[part 1 of 3: packages /HuaweiMDC to /HuaweiMDC/exe_manifests/exes]
AUTOSAR XML (schema 00048)
package /HuaweiMDC
  std cpp implementation data type CameraStructContainer: category=STRUCTURE
    namespaces:
      symbol props iflyauto
      symbol props camera_struct_container
    cpp implementation data type element meta_data: type-reference=String
    cpp implementation data type element camera_data: type-reference=rawBuffer
package /HuaweiMDC/process_manifests/processes
  18 x process, all with log-trace-default-log-level=INFO, log-trace-log-modes=NETWORK:
    com_service_pnc_node_libProcess1: design=com_service_pnc_node_libProcessDesign2, executable=com_service_pnc_node_exec
    control_libProcess2: design=control_libProcessDesign3, executable=control_exec
    obstacle_fusion_libProcess3: design=obstacle_fusion_libProcessDesign4, executable=obstacle_fusion_exec
    static_fusion_libProcess4: design=static_fusion_libProcessDesign5, executable=static_fusion_exec
    finite_state_manager_libProcess5: design=finite_state_manager_libProcessDesign6, executable=finite_state_manager_exec
    localization_libProcess7: design=localization_libProcessDesign8, executable=localization_exec
    ehr_libProcess8: design=ehr_libProcessDesign9, executable=ehr_exec
    panorama_view_camera_perception_libProcess10: design=panorama_view_camera_perception_libProcessDesign11, executable=panorama_view_camera_perception_exec
    uss_perception_libProcess12: design=uss_perception_libProcessDesign13, executable=uss_perception_exec
    planning_libProcess13: design=planning_libProcessDesign14, executable=planning_exec
    camera_node_around_view_libProcess15: design=camera_node_around_view_libProcessDesign16, executable=camera_node_around_view_exec
    camera_node_panorama_view_libProcess16: design=camera_node_panorama_view_libProcessDesign17, executable=camera_node_panorama_view_exec
    gnss_service_node_libProcess17: design=gnss_service_node_libProcessDesign18, executable=gnss_service_node_exec
    soc_a_communication_libProcess18: design=soc_a_communication_libProcessDesign19, executable=soc_a_communication_exec
    soc_b_communication_libProcess19: design=soc_b_communication_libProcessDesign20, executable=soc_b_communication_exec
    common_swc_libProcess22: design=common_swc_libProcessDesign23, executable=common_swc_exec1
    common_swc_libProcess23: design=common_swc_libProcessDesign24, executable=common_swc_exec2
    calibration_libProcess20: design=calibration_libProcessDesign21, executable=calibration_exec
package /HuaweiMDC/process_manifests/processDesigns
  19 x process design:
    com_service_pnc_node_libProcessDesign2: executable=com_service_pnc_node_exec
    control_libProcessDesign3: executable=control_exec
    obstacle_fusion_libProcessDesign4: executable=obstacle_fusion_exec
    static_fusion_libProcessDesign5: executable=static_fusion_exec
    finite_state_manager_libProcessDesign6: executable=finite_state_manager_exec
    localization_libProcessDesign8: executable=localization_exec
    ehr_libProcessDesign9: executable=ehr_exec
    panorama_view_camera_perception_libProcessDesign11: executable=panorama_view_camera_perception_exec
    uss_perception_libProcessDesign13: executable=uss_perception_exec
    planning_libProcessDesign14: executable=planning_exec
    camera_node_around_view_libProcessDesign16: executable=camera_node_around_view_exec
    camera_node_panorama_view_libProcessDesign17: executable=camera_node_panorama_view_exec
    gnss_service_node_libProcessDesign18: executable=gnss_service_node_exec
    soc_a_communication_libProcessDesign19: executable=soc_a_communication_exec
    soc_b_communication_libProcessDesign20: executable=soc_b_communication_exec
    diagnosis_b_libProcessDesign22
    common_swc_libProcessDesign23: executable=common_swc_exec1
    common_swc_libProcessDesign24: executable=common_swc_exec2
    calibration_libProcessDesign21: executable=calibration_exec
package /HuaweiMDC/process_manifests/processToMachineMappingSets
  17 x process to machine mapping set:
    ProcessToMachineMappingSet_panorama_view_camera_perception_libProcess10
      process to machine mapping processToMachineMapping1: machine=MdcSocBMachine, process=panorama_view_camera_perception_libProcess10
    ProcessToMachineMappingSet_camera_node_panorama_view_libProcess16
      process to machine mapping processToMachineMapping3: machine=MdcSocBMachine, process=camera_node_panorama_view_libProcess16
    ProcessToMachineMappingSet_camera_node_around_view_libProcess15
      process to machine mapping processToMachineMapping5: machine=MdcSocAMachine, process=camera_node_around_view_libProcess15
    ProcessToMachineMappingSet_soc_a_communication_libProcess18
      process to machine mapping processToMachineMapping6: machine=MdcSocAMachine, process=soc_a_communication_libProcess18
    ProcessToMachineMappingSet_ehr_libProcess8
      process to machine mapping processToMachineMapping11: machine=MdcSocBMachine, process=ehr_libProcess8
    ProcessToMachineMappingSet_diagnosis_b_libProcess21
      process to machine mapping processToMachineMapping12: machine=MdcSocBMachine
    ProcessToMachineMappingSet_soc_b_communication_libProcess19
      process to machine mapping processToMachineMapping18: machine=MdcSocBMachine, process=soc_b_communication_libProcess19
    ProcessToMachineMappingSet_gnss_service_node_libProcess17
      process to machine mapping processToMachineMapping19: machine=MdcSocBMachine, process=gnss_service_node_libProcess17
    ProcessToMachineMappingSet_localization_libProcess7
      process to machine mapping processToMachineMapping21: machine=MdcSocBMachine, process=localization_libProcess7
    ProcessToMachineMappingSet_uss_perception_libProcess12
      process to machine mapping processToMachineMapping22: machine=MdcSocBMachine, process=uss_perception_libProcess12
    ProcessToMachineMappingSet_static_fusion_libProcess4
      process to machine mapping processToMachineMapping30: machine=MdcSocAMachine, process=static_fusion_libProcess4
    ProcessToMachineMappingSet_control_libProcess2
      process to machine mapping processToMachineMapping32: machine=MdcSocAMachine, process=control_libProcess2
    ProcessToMachineMappingSet_planning_libProcess13
      process to machine mapping processToMachineMapping32: machine=MdcSocAMachine, process=planning_libProcess13
    ProcessToMachineMappingSet_obstacle_fusion_libProcess3
      process to machine mapping processToMachineMapping32: machine=MdcSocAMachine, process=obstacle_fusion_libProcess3
    ProcessToMachineMappingSet_com_service_pnc_node_libProcess1
      process to machine mapping processToMachineMapping32: machine=MdcSocAMachine, process=com_service_pnc_node_libProcess1
    ProcessToMachineMappingSet_calibration_libProcess20
      process to machine mapping processToMachineMapping32: machine=MdcSocBMachine, process=calibration_libProcess20
    ProcessToMachineMappingSet_finite_state_manager_libProcess5
      process to machine mapping processToMachineMapping31: machine=MdcSocBMachine, process=finite_state_manager_libProcess5
package /HuaweiMDC/exe_manifests/swcs
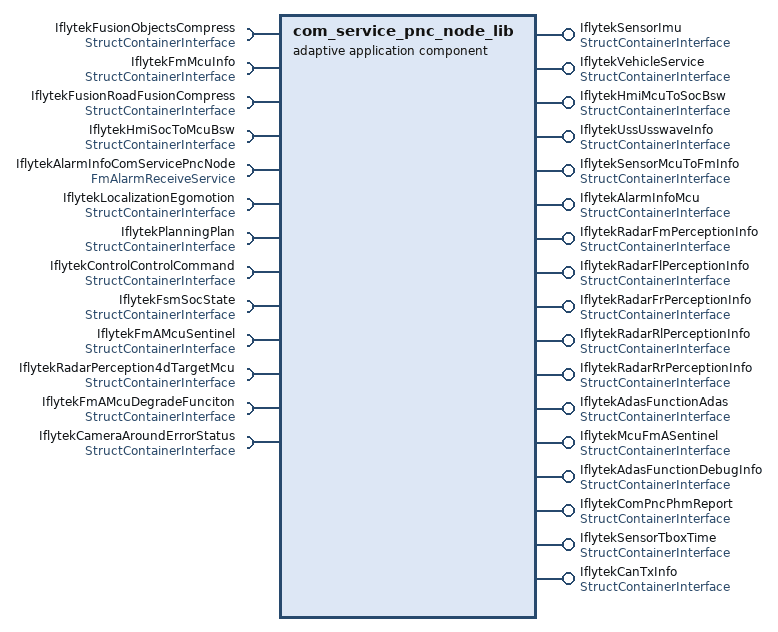
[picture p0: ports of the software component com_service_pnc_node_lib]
  adaptive application sw component type com_service_pnc_node_lib
    12 x provide port, all with provided-interface=StructContainerInterface:
      IflytekSensorImu
      IflytekVehicleService
      IflytekHmiMcuToSocBsw
      IflytekUssUsswaveInfo
      IflytekSensorMcuToFmInfo
      IflytekAlarmInfoMcu
      IflytekRadarFmPerceptionInfo
      IflytekRadarFlPerceptionInfo
      IflytekRadarFrPerceptionInfo
      IflytekRadarRlPerceptionInfo
      IflytekRadarRrPerceptionInfo
      IflytekAdasFunctionAdas
    9 x require port:
      IflytekFusionObjectsCompress: required-interface=StructContainerInterface
      IflytekFmMcuInfo: required-interface=StructContainerInterface
      IflytekFusionRoadFusionCompress: required-interface=StructContainerInterface
      IflytekHmiSocToMcuBsw: required-interface=StructContainerInterface
      IflytekAlarmInfoComServicePncNode: required-interface=FmAlarmReceiveService
      IflytekLocalizationEgomotion: required-interface=StructContainerInterface
      IflytekPlanningPlan: required-interface=StructContainerInterface
      IflytekControlControlCommand: required-interface=StructContainerInterface
      IflytekFsmSocState: required-interface=StructContainerInterface
    provide port IflytekMcuFmASentinel: provided-interface=StructContainerInterface
    require port IflytekFmAMcuSentinel: required-interface=StructContainerInterface
    provide port IflytekAdasFunctionDebugInfo: provided-interface=StructContainerInterface
    require port IflytekRadarPerception4dTargetMcu: required-interface=StructContainerInterface
    require port IflytekFmAMcuDegradeFunciton: required-interface=StructContainerInterface
    provide port IflytekComPncPhmReport: provided-interface=StructContainerInterface
    provide port IflytekSensorTboxTime: provided-interface=StructContainerInterface
    require port IflytekCameraAroundErrorStatus: required-interface=StructContainerInterface
    provide port IflytekCanTxInfo: provided-interface=StructContainerInterface
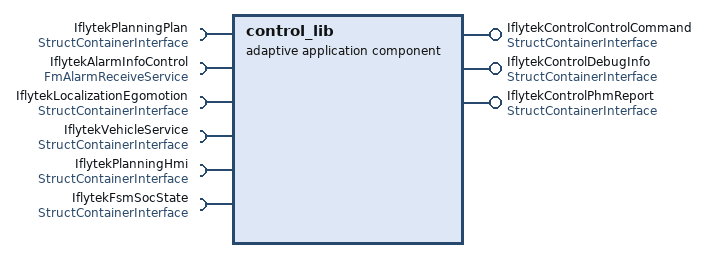
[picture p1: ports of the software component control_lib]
  adaptive application sw component type control_lib
    provide port IflytekControlControlCommand: provided-interface=StructContainerInterface
    6 x require port:
      IflytekPlanningPlan: required-interface=StructContainerInterface
      IflytekAlarmInfoControl: required-interface=FmAlarmReceiveService
      IflytekLocalizationEgomotion: required-interface=StructContainerInterface
      IflytekVehicleService: required-interface=StructContainerInterface
      IflytekPlanningHmi: required-interface=StructContainerInterface
      IflytekFsmSocState: required-interface=StructContainerInterface
    provide port IflytekControlDebugInfo: provided-interface=StructContainerInterface
    provide port IflytekControlPhmReport: provided-interface=StructContainerInterface
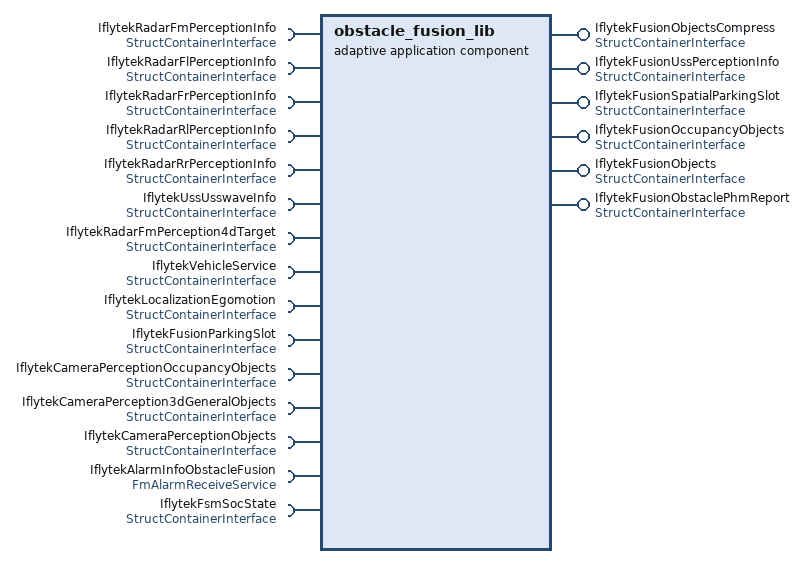
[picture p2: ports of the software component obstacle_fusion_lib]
  adaptive application sw component type obstacle_fusion_lib
    5 x require port, all with required-interface=StructContainerInterface:
      IflytekRadarFmPerceptionInfo
      IflytekRadarFlPerceptionInfo
      IflytekRadarFrPerceptionInfo
      IflytekRadarRlPerceptionInfo
      IflytekRadarRrPerceptionInfo
    provide port IflytekFusionObjectsCompress: provided-interface=StructContainerInterface
    4 x require port, all with required-interface=StructContainerInterface:
      IflytekUssUsswaveInfo
      IflytekRadarFmPerception4dTarget
      IflytekVehicleService
      IflytekLocalizationEgomotion
    4 x provide port, all with provided-interface=StructContainerInterface:
      IflytekFusionUssPerceptionInfo
      IflytekFusionSpatialParkingSlot
      IflytekFusionOccupancyObjects
      IflytekFusionObjects
    6 x require port:
      IflytekFusionParkingSlot: required-interface=StructContainerInterface
      IflytekCameraPerceptionOccupancyObjects: required-interface=StructContainerInterface
      IflytekCameraPerception3dGeneralObjects: required-interface=StructContainerInterface
      IflytekCameraPerceptionObjects: required-interface=StructContainerInterface
      IflytekAlarmInfoObstacleFusion: required-interface=FmAlarmReceiveService
      IflytekFsmSocState: required-interface=StructContainerInterface
    provide port IflytekFusionObstaclePhmReport: provided-interface=StructContainerInterface
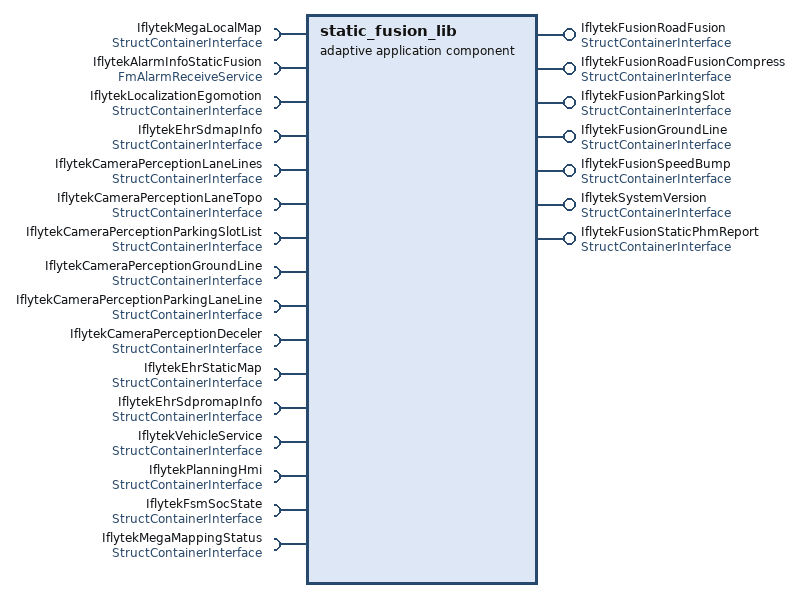
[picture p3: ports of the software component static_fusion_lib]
  adaptive application sw component type static_fusion_lib
    provide port IflytekFusionRoadFusion: provided-interface=StructContainerInterface
    provide port IflytekFusionRoadFusionCompress: provided-interface=StructContainerInterface
    provide port IflytekFusionParkingSlot: provided-interface=StructContainerInterface
    require port IflytekMegaLocalMap: required-interface=StructContainerInterface
    provide port IflytekFusionGroundLine: provided-interface=StructContainerInterface
    10 x require port:
      IflytekAlarmInfoStaticFusion: required-interface=FmAlarmReceiveService
      IflytekLocalizationEgomotion: required-interface=StructContainerInterface
      IflytekEhrSdmapInfo: required-interface=StructContainerInterface
      IflytekCameraPerceptionLaneLines: required-interface=StructContainerInterface
      IflytekCameraPerceptionLaneTopo: required-interface=StructContainerInterface
      IflytekCameraPerceptionParkingSlotList: required-interface=StructContainerInterface
      IflytekCameraPerceptionGroundLine: required-interface=StructContainerInterface
      IflytekCameraPerceptionParkingLaneLine: required-interface=StructContainerInterface
      IflytekCameraPerceptionDeceler: required-interface=StructContainerInterface
      IflytekEhrStaticMap: required-interface=StructContainerInterface
    provide port IflytekFusionSpeedBump: provided-interface=StructContainerInterface
    provide port IflytekSystemVersion: provided-interface=StructContainerInterface
    4 x require port, all with required-interface=StructContainerInterface:
      IflytekEhrSdpromapInfo
      IflytekVehicleService
      IflytekPlanningHmi
      IflytekFsmSocState
    provide port IflytekFusionStaticPhmReport: provided-interface=StructContainerInterface
    require port IflytekMegaMappingStatus: required-interface=StructContainerInterface
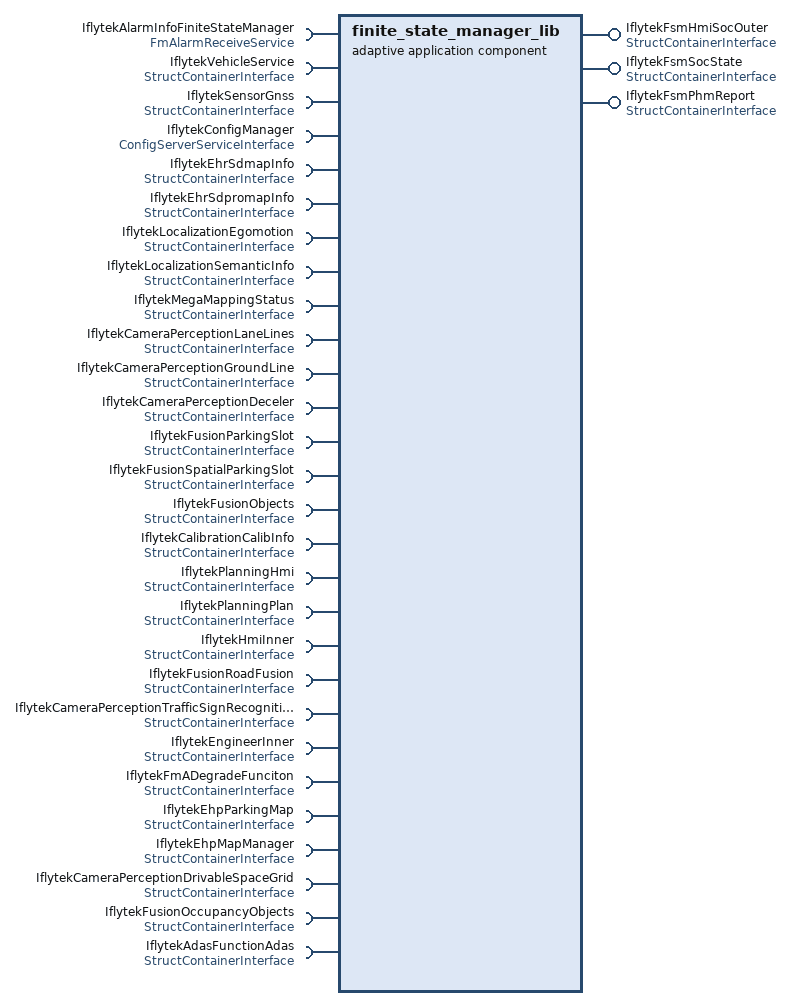
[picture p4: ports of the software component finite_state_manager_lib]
  adaptive application sw component type finite_state_manager_lib
    19 x require port:
      IflytekAlarmInfoFiniteStateManager: required-interface=FmAlarmReceiveService
      IflytekVehicleService: required-interface=StructContainerInterface
      IflytekSensorGnss: required-interface=StructContainerInterface
      IflytekConfigManager: required-interface=ConfigServerServiceInterface
      IflytekEhrSdmapInfo: required-interface=StructContainerInterface
      IflytekEhrSdpromapInfo: required-interface=StructContainerInterface
      IflytekLocalizationEgomotion: required-interface=StructContainerInterface
      IflytekLocalizationSemanticInfo: required-interface=StructContainerInterface
      IflytekMegaMappingStatus: required-interface=StructContainerInterface
      IflytekCameraPerceptionLaneLines: required-interface=StructContainerInterface
      IflytekCameraPerceptionGroundLine: required-interface=StructContainerInterface
      IflytekCameraPerceptionDeceler: required-interface=StructContainerInterface
      IflytekFusionParkingSlot: required-interface=StructContainerInterface
      IflytekFusionSpatialParkingSlot: required-interface=StructContainerInterface
      IflytekFusionObjects: required-interface=StructContainerInterface
      IflytekCalibrationCalibInfo: required-interface=StructContainerInterface
      IflytekPlanningHmi: required-interface=StructContainerInterface
      IflytekPlanningPlan: required-interface=StructContainerInterface
      IflytekHmiInner: required-interface=StructContainerInterface
    provide port IflytekFsmHmiSocOuter: provided-interface=StructContainerInterface
    provide port IflytekFsmSocState: provided-interface=StructContainerInterface
    4 x require port, all with required-interface=StructContainerInterface:
      IflytekFusionRoadFusion
      IflytekCameraPerceptionTrafficSignRecognition
      IflytekEngineerInner
      IflytekFmADegradeFunciton
    provide port IflytekFsmPhmReport: provided-interface=StructContainerInterface
    5 x require port, all with required-interface=StructContainerInterface:
      IflytekEhpParkingMap
      IflytekEhpMapManager
      IflytekCameraPerceptionDrivableSpaceGrid
      IflytekFusionOccupancyObjects
      IflytekAdasFunctionAdas
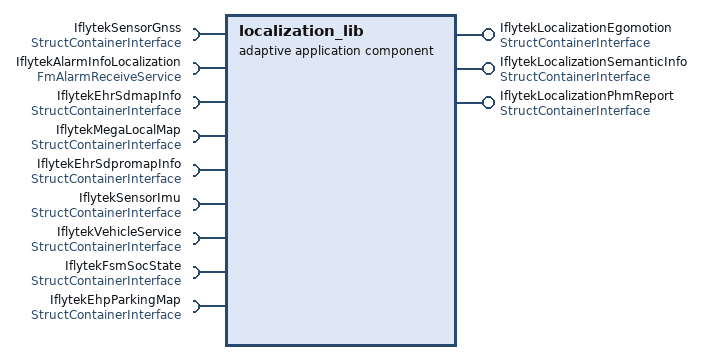
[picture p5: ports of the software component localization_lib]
  adaptive application sw component type localization_lib
    provide port IflytekLocalizationEgomotion: provided-interface=StructContainerInterface
    require port IflytekSensorGnss: required-interface=StructContainerInterface
    require port IflytekAlarmInfoLocalization: required-interface=FmAlarmReceiveService
    require port IflytekEhrSdmapInfo: required-interface=StructContainerInterface
    provide port IflytekLocalizationSemanticInfo: provided-interface=StructContainerInterface
    5 x require port, all with required-interface=StructContainerInterface:
      IflytekMegaLocalMap
      IflytekEhrSdpromapInfo
      IflytekSensorImu
      IflytekVehicleService
      IflytekFsmSocState
    provide port IflytekLocalizationPhmReport: provided-interface=StructContainerInterface
    require port IflytekEhpParkingMap: required-interface=StructContainerInterface
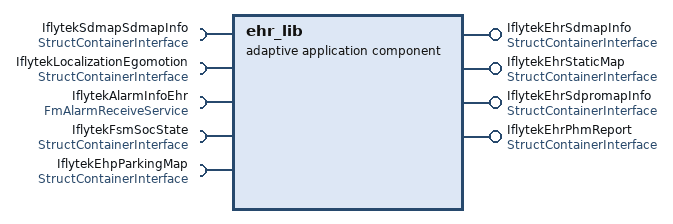
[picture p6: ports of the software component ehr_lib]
  adaptive application sw component type ehr_lib
    provide port IflytekEhrSdmapInfo: provided-interface=StructContainerInterface
    require port IflytekSdmapSdmapInfo: required-interface=StructContainerInterface
    require port IflytekLocalizationEgomotion: required-interface=StructContainerInterface
    require port IflytekAlarmInfoEhr: required-interface=FmAlarmReceiveService
    provide port IflytekEhrStaticMap: provided-interface=StructContainerInterface
    provide port IflytekEhrSdpromapInfo: provided-interface=StructContainerInterface
    require port IflytekFsmSocState: required-interface=StructContainerInterface
    provide port IflytekEhrPhmReport: provided-interface=StructContainerInterface
    require port IflytekEhpParkingMap: required-interface=StructContainerInterface
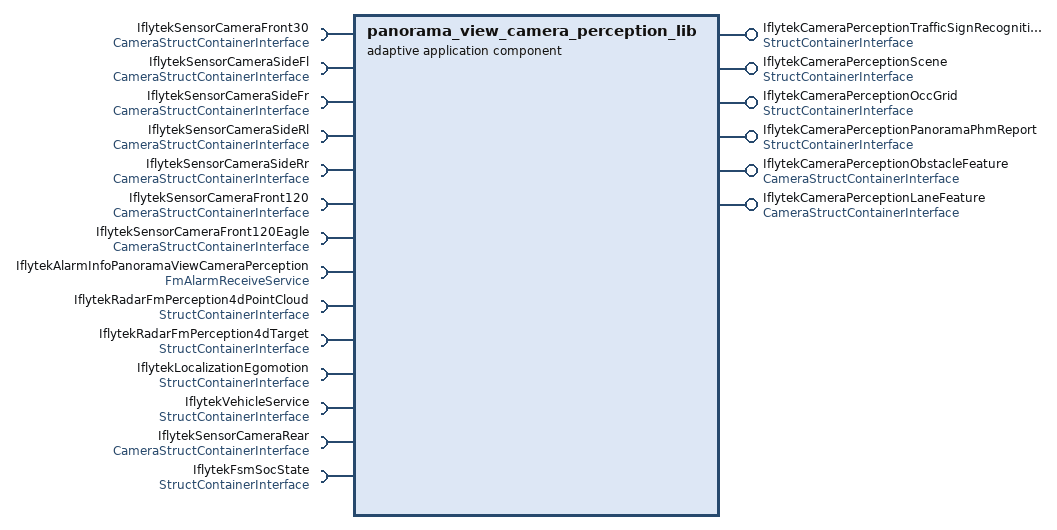
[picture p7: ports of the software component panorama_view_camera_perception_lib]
  adaptive application sw component type panorama_view_camera_perception_lib
    8 x require port:
      IflytekSensorCameraFront30: required-interface=CameraStructContainerInterface
      IflytekSensorCameraSideFl: required-interface=CameraStructContainerInterface
      IflytekSensorCameraSideFr: required-interface=CameraStructContainerInterface
      IflytekSensorCameraSideRl: required-interface=CameraStructContainerInterface
      IflytekSensorCameraSideRr: required-interface=CameraStructContainerInterface
      IflytekSensorCameraFront120: required-interface=CameraStructContainerInterface
      IflytekSensorCameraFront120Eagle: required-interface=CameraStructContainerInterface
      IflytekAlarmInfoPanoramaViewCameraPerception: required-interface=FmAlarmReceiveService
    provide port IflytekCameraPerceptionTrafficSignRecognition: provided-interface=StructContainerInterface
    require port IflytekRadarFmPerception4dPointCloud: required-interface=StructContainerInterface
    require port IflytekRadarFmPerception4dTarget: required-interface=StructContainerInterface
    require port IflytekLocalizationEgomotion: required-interface=StructContainerInterface
    provide port IflytekCameraPerceptionScene: provided-interface=StructContainerInterface
    provide port IflytekCameraPerceptionOccGrid: provided-interface=StructContainerInterface
    require port IflytekVehicleService: required-interface=StructContainerInterface
    require port IflytekSensorCameraRear: required-interface=CameraStructContainerInterface
    require port IflytekFsmSocState: required-interface=StructContainerInterface
    provide port IflytekCameraPerceptionPanoramaPhmReport: provided-interface=StructContainerInterface
    provide port IflytekCameraPerceptionObstacleFeature: provided-interface=CameraStructContainerInterface
    provide port IflytekCameraPerceptionLaneFeature: provided-interface=CameraStructContainerInterface
  adaptive application sw component type mobileye_perception_lib
  adaptive application sw component type uss_perception_lib
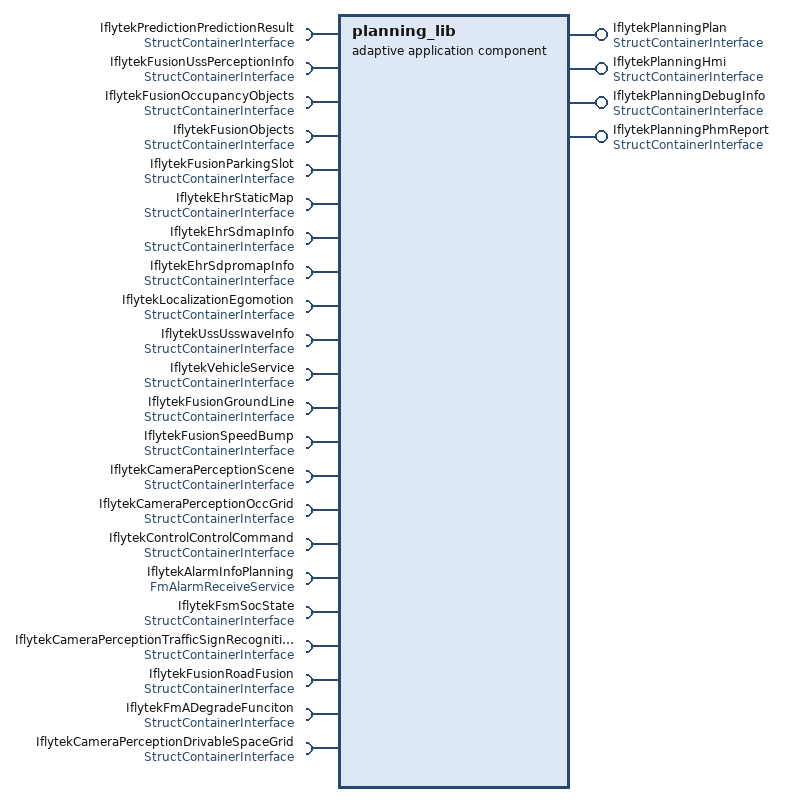
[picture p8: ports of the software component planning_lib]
  adaptive application sw component type planning_lib
    provide port IflytekPlanningPlan: provided-interface=StructContainerInterface
    16 x require port, all with required-interface=StructContainerInterface:
      IflytekPredictionPredictionResult
      IflytekFusionUssPerceptionInfo
      IflytekFusionOccupancyObjects
      IflytekFusionObjects
      IflytekFusionParkingSlot
      IflytekEhrStaticMap
      IflytekEhrSdmapInfo
      IflytekEhrSdpromapInfo
      IflytekLocalizationEgomotion
      IflytekUssUsswaveInfo
      IflytekVehicleService
      IflytekFusionGroundLine
      IflytekFusionSpeedBump
      IflytekCameraPerceptionScene
      IflytekCameraPerceptionOccGrid
      IflytekControlControlCommand
    provide port IflytekPlanningHmi: provided-interface=StructContainerInterface
    4 x require port:
      IflytekAlarmInfoPlanning: required-interface=FmAlarmReceiveService
      IflytekFsmSocState: required-interface=StructContainerInterface
      IflytekCameraPerceptionTrafficSignRecognition: required-interface=StructContainerInterface
      IflytekFusionRoadFusion: required-interface=StructContainerInterface
    provide port IflytekPlanningDebugInfo: provided-interface=StructContainerInterface
    require port IflytekFmADegradeFunciton: required-interface=StructContainerInterface
    provide port IflytekPlanningPhmReport: provided-interface=StructContainerInterface
    require port IflytekCameraPerceptionDrivableSpaceGrid: required-interface=StructContainerInterface
  adaptive application sw component type prediction_lib
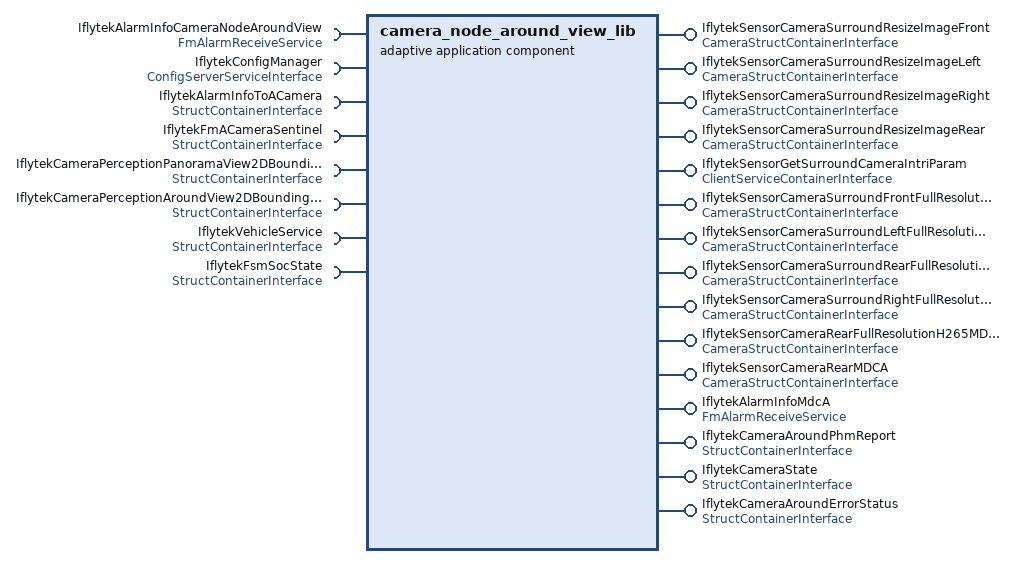
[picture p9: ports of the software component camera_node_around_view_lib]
  adaptive application sw component type camera_node_around_view_lib
    4 x provide port, all with provided-interface=CameraStructContainerInterface:
      IflytekSensorCameraSurroundResizeImageFront
      IflytekSensorCameraSurroundResizeImageLeft
      IflytekSensorCameraSurroundResizeImageRight
      IflytekSensorCameraSurroundResizeImageRear
    require port IflytekAlarmInfoCameraNodeAroundView: required-interface=FmAlarmReceiveService
    8 x provide port:
      IflytekSensorGetSurroundCameraIntriParam: provided-interface=ClientServiceContainerInterface
      IflytekSensorCameraSurroundFrontFullResolutionH265: provided-interface=CameraStructContainerInterface
      IflytekSensorCameraSurroundLeftFullResolutionH265: provided-interface=CameraStructContainerInterface
      IflytekSensorCameraSurroundRearFullResolutionH265: provided-interface=CameraStructContainerInterface
      IflytekSensorCameraSurroundRightFullResolutionH265: provided-interface=CameraStructContainerInterface
      IflytekSensorCameraRearFullResolutionH265MDCA: provided-interface=CameraStructContainerInterface
      IflytekSensorCameraRearMDCA: provided-interface=CameraStructContainerInterface
      IflytekAlarmInfoMdcA: provided-interface=FmAlarmReceiveService
    5 x require port:
      IflytekConfigManager: required-interface=ConfigServerServiceInterface
      IflytekAlarmInfoToACamera: required-interface=StructContainerInterface
      IflytekFmACameraSentinel: required-interface=StructContainerInterface
      IflytekCameraPerceptionPanoramaView2DBoundingBoxes: required-interface=StructContainerInterface
      IflytekCameraPerceptionAroundView2DBoundingBoxes: required-interface=StructContainerInterface
    provide port IflytekCameraAroundPhmReport: provided-interface=StructContainerInterface
    require port IflytekVehicleService: required-interface=StructContainerInterface
    require port IflytekFsmSocState: required-interface=StructContainerInterface
    provide port IflytekCameraState: provided-interface=StructContainerInterface
    provide port IflytekCameraAroundErrorStatus: provided-interface=StructContainerInterface
  adaptive application sw component type camera_node_panorama_view_lib
    8 x provide port, all with provided-interface=CameraStructContainerInterface:
      IflytekSensorCameraFront30
      IflytekSensorCameraSideFl
      IflytekSensorCameraSideFr
      IflytekSensorCameraSideRl
      IflytekSensorCameraSideRr
      IflytekSensorCameraRear
      IflytekSensorCameraFront120
      IflytekSensorCameraFront120Eagle
    require port IflytekAlarmInfoCameraNodePanoramaView: required-interface=FmAlarmReceiveService
    8 x provide port:
      IflytekSensorCameraFront120FullResolutionH265: provided-interface=CameraStructContainerInterface
      IflytekSensorGetPanoramaCameraIntriParam: provided-interface=ClientServiceContainerInterface
      IflytekSensorCameraFront30FullResolutionH265: provided-interface=CameraStructContainerInterface
      IflytekSensorCameraSideFlFullResolutionH265: provided-interface=CameraStructContainerInterface
      IflytekSensorCameraSideFrFullResolutionH265: provided-interface=CameraStructContainerInterface
      IflytekSensorCameraSideRlFullResolutionH265: provided-interface=CameraStructContainerInterface
      IflytekSensorCameraSideRrFullResolutionH265: provided-interface=CameraStructContainerInterface
      IflytekSensorCameraRearFullResolutionH265: provided-interface=CameraStructContainerInterface
    require port IflytekSensorCameraRearMDCA: required-interface=CameraStructContainerInterface
    require port IflytekConfigManager: required-interface=ConfigServerServiceInterface
    provide port IflytekAlarmInfoMdcB: provided-interface=FmAlarmReceiveService
    require port IflytekAlarmInfoToBCamera: required-interface=StructContainerInterface
    require port IflytekCameraPerceptionPanoramaView2DBoundingBoxes: required-interface=StructContainerInterface
    provide port IflytekSensorCameraFront120FullResolutionClearH265: provided-interface=CameraStructContainerInterface
    provide port IflytekCameraPanoramaPhmReport: provided-interface=StructContainerInterface
  adaptive application sw component type gnss_service_node_lib
    provide port IflytekSensorGnss: provided-interface=StructContainerInterface
    require port IflytekAlarmInfoGnssServiceNode: required-interface=FmAlarmReceiveService
    provide port IflytekGnssPhmReport: provided-interface=StructContainerInterface
    require port IflytekSensorTboxTime: required-interface=StructContainerInterface
  adaptive application sw component type soc_a_communication_lib
    10 x require port, all with required-interface=CameraStructContainerInterface:
      IflytekSensorCameraFront120Eagle_copy
      IflytekSensorCameraSideRl_copy
      IflytekSensorCameraSideFl_copy
      IflytekSensorCameraFront120_copy
      IflytekSensorCameraSideFr_copy
      IflytekSensorCameraFront120Eagle_copy
      IflytekSensorCameraSideRl_copy
      IflytekSensorCameraSideFl_copy
      IflytekSensorCameraFront120_copy
      IflytekSensorCameraSideFr_copy
    provide port IflytekEhrSdmapInfo: provided-interface=StructContainerInterface
    require port IflytekAlarmInfoSocACommunication: required-interface=FmAlarmReceiveService
    provide port IflytekLocalizationEgomotion: provided-interface=StructContainerInterface
    provide port IflytekLocalizationSemanticInfo: provided-interface=StructContainerInterface
    require port IflytekMegaMappingStatus: required-interface=StructContainerInterface
    require port IflytekMegaLocalMap: required-interface=StructContainerInterface
    11 x provide port:
      IflytekEhrStaticMap: provided-interface=StructContainerInterface
      IflytekSensorCameraFront120FullResolutionH265: provided-interface=CameraStructContainerInterface
      IflytekSensorGetPanoramaCameraIntriParam: provided-interface=ClientServiceContainerInterface
      IflytekSensorWriteFile: provided-interface=ClientServiceContainerInterface
      IflytekAlarmInfoMcu: provided-interface=StructContainerInterface
      IflytekAlarmInfoSoc: provided-interface=StructContainerInterface
      IflytekSensorCameraFront30FullResolutionH265: provided-interface=CameraStructContainerInterface
      IflytekSensorCameraSideFlFullResolutionH265: provided-interface=CameraStructContainerInterface
      IflytekSensorCameraSideFrFullResolutionH265: provided-interface=CameraStructContainerInterface
      IflytekSensorCameraSideRlFullResolutionH265: provided-interface=CameraStructContainerInterface
      IflytekSensorCameraSideRrFullResolutionH265: provided-interface=CameraStructContainerInterface
    require port IflytekCameraPerceptionObjects: required-interface=StructContainerInterface
    provide port IflytekSensorMcuToFmInfo: provided-interface=StructContainerInterface
    require port IflytekSensorCameraRearMDCA: required-interface=CameraStructContainerInterface
    provide port IflytekEhrSdpromapInfo: provided-interface=StructContainerInterface
    7 x require port:
      IflytekSensorCameraSurroundResizeImageFront: required-interface=CameraStructContainerInterface
      IflytekSensorCameraSurroundResizeImageLeft: required-interface=CameraStructContainerInterface
      IflytekSensorCameraSurroundResizeImageRear: required-interface=CameraStructContainerInterface
      IflytekSensorCameraSurroundResizeImageRight: required-interface=CameraStructContainerInterface
      IflytekSensorImu: required-interface=StructContainerInterface
      IflytekVehicleService: required-interface=StructContainerInterface
      IflytekHmiMcuToSocBsw: required-interface=StructContainerInterface
    provide port IflytekHmiSocToMcuBsw: provided-interface=StructContainerInterface
    provide port IflytekRadarFmPerception4dTarget: provided-interface=StructContainerInterface
    require port IflytekFusionObjects: required-interface=StructContainerInterface
    provide port IflytekCameraPerceptionScene: provided-interface=StructContainerInterface
    provide port IflytekCameraPerceptionTrafficSignRecognition: provided-interface=StructContainerInterface
    provide port IflytekCameraPerceptionOccGrid: provided-interface=StructContainerInterface
    7 x require port, all with required-interface=StructContainerInterface:
      IflytekCameraPerceptionLaneLines
      IflytekCameraPerceptionGroundLine
      IflytekCameraPerceptionDeceler
      IflytekFusionParkingSlot
      IflytekFusionSpatialParkingSlot
      IflytekPlanningHmi
      IflytekPlanningPlan
    provide port IflytekFsmSocState: provided-interface=StructContainerInterface
    26 x require port:
      IflytekSensorCameraSurroundFrontFullResolutionH265: required-interface=CameraStructContainerInterface
      IflytekSensorCameraSurroundLeftFullResolutionH265: required-interface=CameraStructContainerInterface
      IflytekSensorCameraSurroundRearFullResolutionH265: required-interface=CameraStructContainerInterface
      IflytekSensorCameraSurroundRightFullResolutionH265: required-interface=CameraStructContainerInterface
      IflytekCameraPerceptionLaneTopo: required-interface=StructContainerInterface
      IflytekPredictionPredictionResult: required-interface=StructContainerInterface
      IflytekCameraPerceptionOccupancyObjects: required-interface=StructContainerInterface
      IflytekFusionRoadFusion: required-interface=StructContainerInterface
      IflytekCameraPerception3dGeneralObjects: required-interface=StructContainerInterface
      IflytekCameraPerceptionParkingSlotList: required-interface=StructContainerInterface
      IflytekCameraPerceptionParkingLaneLine: required-interface=StructContainerInterface
      IflytekFusionObjectsCompress: required-interface=StructContainerInterface
      IflytekFusionUssPerceptionInfo: required-interface=StructContainerInterface
      IflytekFusionOccupancyObjects: required-interface=StructContainerInterface
      IflytekFusionRoadFusionCompress: required-interface=StructContainerInterface
      IflytekFusionGroundLine: required-interface=StructContainerInterface
      IflytekFusionSpeedBump: required-interface=StructContainerInterface
      IflytekUssUsswaveInfo: required-interface=StructContainerInterface
      IflytekRadarFlPerceptionInfo: required-interface=StructContainerInterface
      IflytekRadarFrPerceptionInfo: required-interface=StructContainerInterface
      IflytekRadarRlPerceptionInfo: required-interface=StructContainerInterface
      IflytekRadarRrPerceptionInfo: required-interface=StructContainerInterface
      IflytekAdasFunctionAdas: required-interface=StructContainerInterface
      IflytekControlControlCommand: required-interface=StructContainerInterface
      IflytekAlarmInfoFmAService: required-interface=StructContainerInterface
      IflytekDTCInfoFmAService: required-interface=StructContainerInterface
    provide port IflytekPostSaleCalibrationActivation: provided-interface=ClientServiceContainerInterface
    provide port IflytekPostSaleCalibrationStop: provided-interface=ClientServiceContainerInterface
    provide port IflytekPostSaleCalibrationResult: provided-interface=ClientServiceContainerInterface
    require port IflytekSystemVersion: required-interface=StructContainerInterface
    require port IflytekFdlTriggerAck: required-interface=StructContainerInterface
    provide port IflytekFdlTrigger: provided-interface=StructContainerInterface
    require port IflytekPlanningDebugInfo: required-interface=StructContainerInterface
    require port IflytekControlDebugInfo: required-interface=StructContainerInterface
    require port IflytekAdasFunctionDebugInfo: required-interface=StructContainerInterface
    provide port IflytekRadarPerception4dTargetMcu: provided-interface=StructContainerInterface
    provide port IflytekEngineerInner: provided-interface=StructContainerInterface
    8 x require port:
      IflytekFmADegradeFunciton: required-interface=StructContainerInterface
      IflytekCameraPerceptionPanoramaView2DBoundingBoxes: required-interface=StructContainerInterface
      IflytekSensorCameraRearFullResolutionH265MDCA: required-interface=CameraStructContainerInterface
      IflytekFmAMcuSentinel: required-interface=StructContainerInterface
      IflytekMcuFmASentinel: required-interface=StructContainerInterface
      IflytekCameraPerceptionAroundView2DBoundingBoxes: required-interface=StructContainerInterface
      IflytekCameraPerception3dOccupancyObjects: required-interface=StructContainerInterface
      IflytekSensorTboxTime: required-interface=StructContainerInterface
    provide port IflytekFdlUploadState: provided-interface=StructContainerInterface
    provide port IflytekFdlNetStatCheck: provided-interface=ClientServiceContainerInterface
    provide port IflytekDiskSpaceInfoPhmBOta: provided-interface=StructContainerInterface
    6 x require port, all with required-interface=StructContainerInterface:
      IflytekDiskCleanRequest
      IflytekDiskStatePhmAFdl
      IflytekDiskCleanRequestPhmAFdl
      IflytekEhpParkingMap
      IflytekEhpParkingMapFileInfo
      IflytekEhpMapManager
    provide port IflytekSensorGnss: provided-interface=StructContainerInterface
    provide port IflytekOtaLogUploadRequest: provided-interface=ClientServiceContainerInterface
    provide port IflytekCalibrationCalibInfo: provided-interface=StructContainerInterface
    require port IflytekSystemAProcessLoading: required-interface=StructContainerInterface
    require port IflytekCameraPerceptionDrivableSpaceGrid: required-interface=StructContainerInterface
    provide port IflytekCameraPerceptionObstacleFeature: provided-interface=CameraStructContainerInterface
    provide port IflytekCameraPerceptionLaneFeature: provided-interface=CameraStructContainerInterface
    require port IflytekEhpParkingMapToHmi: required-interface=StructContainerInterface
    require port IflytekCanTxInfo: required-interface=StructContainerInterface
  adaptive application sw component type soc_b_communication_lib
    5 x require port:
      IflytekEhrSdmapInfo: required-interface=StructContainerInterface
      IflytekAlarmInfoSocBCommunication: required-interface=FmAlarmReceiveService
      IflytekLocalizationEgomotion: required-interface=StructContainerInterface
      IflytekSensorGnss: required-interface=StructContainerInterface
      IflytekLocalizationSemanticInfo: required-interface=StructContainerInterface
    provide port IflytekMegaMappingStatus: provided-interface=StructContainerInterface
    provide port IflytekMegaLocalMap: provided-interface=StructContainerInterface
    9 x require port:
      IflytekEhrStaticMap: required-interface=StructContainerInterface
      IflytekSensorCameraFront120FullResolutionH265: required-interface=CameraStructContainerInterface
      IflytekSensorGetPanoramaCameraIntriParam: required-interface=ClientServiceContainerInterface
      IflytekAlarmInfoSoc: required-interface=StructContainerInterface
      IflytekSensorCameraFront30FullResolutionH265: required-interface=CameraStructContainerInterface
      IflytekSensorCameraSideFlFullResolutionH265: required-interface=CameraStructContainerInterface
      IflytekSensorCameraSideFrFullResolutionH265: required-interface=CameraStructContainerInterface
      IflytekSensorCameraSideRlFullResolutionH265: required-interface=CameraStructContainerInterface
      IflytekSensorCameraSideRrFullResolutionH265: required-interface=CameraStructContainerInterface
    provide port IflytekCameraPerceptionObjects: provided-interface=StructContainerInterface
    provide port IflytekSensorCameraRearMDCA: provided-interface=CameraStructContainerInterface
    4 x require port, all with required-interface=StructContainerInterface:
      IflytekCameraPerceptionTrafficSignRecognition
      IflytekRadarFmPerception4dTarget
      IflytekEhrSdpromapInfo
      IflytekCameraPerceptionOccGrid
    8 x provide port:
      IflytekSensorCameraSurroundResizeImageFront: provided-interface=CameraStructContainerInterface
      IflytekSensorCameraSurroundResizeImageLeft: provided-interface=CameraStructContainerInterface
      IflytekSensorCameraSurroundResizeImageRear: provided-interface=CameraStructContainerInterface
      IflytekSensorCameraSurroundResizeImageRight: provided-interface=CameraStructContainerInterface
      IflytekSensorImu: provided-interface=StructContainerInterface
      IflytekVehicleService: provided-interface=StructContainerInterface
      IflytekHmiMcuToSocBsw: provided-interface=StructContainerInterface
      IflytekFusionObjects: provided-interface=StructContainerInterface
    require port IflytekCalibrationCalibInfo: required-interface=StructContainerInterface
    require port IflytekHmiSocToMcuBsw: required-interface=StructContainerInterface
    require port IflytekCameraPerceptionScene: required-interface=StructContainerInterface
    8 x provide port, all with provided-interface=StructContainerInterface:
      IflytekCameraPerceptionLaneLines
      IflytekCameraPerceptionGroundLine
      IflytekCameraPerceptionDeceler
      IflytekFusionRoadFusion
      IflytekFusionParkingSlot
      IflytekFusionSpatialParkingSlot
      IflytekPlanningPlan
      IflytekPlanningHmi
    require port IflytekFsmSocState: required-interface=StructContainerInterface
    25 x provide port:
      IflytekSensorCameraSurroundFrontFullResolutionH265: provided-interface=CameraStructContainerInterface
      IflytekSensorCameraSurroundLeftFullResolutionH265: provided-interface=CameraStructContainerInterface
      IflytekSensorCameraSurroundRearFullResolutionH265: provided-interface=CameraStructContainerInterface
      IflytekSensorCameraSurroundRightFullResolutionH265: provided-interface=CameraStructContainerInterface
      IflytekCameraPerceptionLaneTopo: provided-interface=StructContainerInterface
      IflytekPredictionPredictionResult: provided-interface=StructContainerInterface
      IflytekCameraPerceptionOccupancyObjects: provided-interface=StructContainerInterface
      IflytekCameraPerception3dGeneralObjects: provided-interface=StructContainerInterface
      IflytekCameraPerceptionParkingSlotList: provided-interface=StructContainerInterface
      IflytekCameraPerceptionParkingLaneLine: provided-interface=StructContainerInterface
      IflytekFusionObjectsCompress: provided-interface=StructContainerInterface
      IflytekFusionUssPerceptionInfo: provided-interface=StructContainerInterface
      IflytekFusionOccupancyObjects: provided-interface=StructContainerInterface
      IflytekFusionRoadFusionCompress: provided-interface=StructContainerInterface
      IflytekFusionGroundLine: provided-interface=StructContainerInterface
      IflytekFusionSpeedBump: provided-interface=StructContainerInterface
      IflytekUssUsswaveInfo: provided-interface=StructContainerInterface
      IflytekRadarFlPerceptionInfo: provided-interface=StructContainerInterface
      IflytekRadarFrPerceptionInfo: provided-interface=StructContainerInterface
      IflytekRadarRlPerceptionInfo: provided-interface=StructContainerInterface
      IflytekRadarRrPerceptionInfo: provided-interface=StructContainerInterface
      IflytekAdasFunctionAdas: provided-interface=StructContainerInterface
      IflytekControlControlCommand: provided-interface=StructContainerInterface
      IflytekDTCInfoFmAService: provided-interface=StructContainerInterface
      IflytekAlarmInfoFmAService: provided-interface=StructContainerInterface
    require port IflytekPostSaleCalibrationActivation: required-interface=ClientServiceContainerInterface
    require port IflytekPostSaleCalibrationStop: required-interface=ClientServiceContainerInterface
    require port IflytekPostSaleCalibrationResult: required-interface=ClientServiceContainerInterface
    provide port IflytekSystemVersion: provided-interface=StructContainerInterface
    require port IflytekFdlTrigger: required-interface=StructContainerInterface
    4 x provide port, all with provided-interface=StructContainerInterface:
      IflytekFdlTriggerAck
      IflytekPlanningDebugInfo
      IflytekControlDebugInfo
      IflytekAdasFunctionDebugInfo
    require port IflytekRadarPerception4dTargetMcu: required-interface=StructContainerInterface
    require port IflytekEngineerInner: required-interface=StructContainerInterface
    8 x provide port:
      IflytekFmADegradeFunciton: provided-interface=StructContainerInterface
      IflytekCameraPerceptionPanoramaView2DBoundingBoxes: provided-interface=StructContainerInterface
      IflytekSensorCameraRearFullResolutionH265MDCA: provided-interface=CameraStructContainerInterface
      IflytekFmAMcuSentinel: provided-interface=StructContainerInterface
      IflytekMcuFmASentinel: provided-interface=StructContainerInterface
      IflytekCameraPerceptionAroundView2DBoundingBoxes: provided-interface=StructContainerInterface
      IflytekCameraPerception3dOccupancyObjects: provided-interface=StructContainerInterface
      IflytekSensorTboxTime: provided-interface=StructContainerInterface
    require port IflytekFdlUploadState: required-interface=StructContainerInterface
    require port IflytekFdlNetStatCheck: required-interface=ClientServiceContainerInterface
    require port IflytekDiskSpaceInfoPhmBOta: required-interface=StructContainerInterface
    6 x provide port, all with provided-interface=StructContainerInterface:
      IflytekDiskCleanRequest
      IflytekDiskStatePhmAFdl
      IflytekDiskCleanRequestPhmAFdl
      IflytekEhpParkingMap
      IflytekEhpParkingMapFileInfo
      IflytekEhpMapManager
    require port IflytekOtaLogUploadRequest: required-interface=ClientServiceContainerInterface
    provide port IflytekSystemAProcessLoading: provided-interface=StructContainerInterface
    provide port IflytekCameraPerceptionDrivableSpaceGrid: provided-interface=StructContainerInterface
    require port IflytekCameraPerceptionObstacleFeature: required-interface=CameraStructContainerInterface
    require port IflytekCameraPerceptionLaneFeature: required-interface=CameraStructContainerInterface
    provide port IflytekEhpParkingMapToHmi: provided-interface=StructContainerInterface
    provide port IflytekCanTxInfo: provided-interface=StructContainerInterface
  adaptive application sw component type common_swc_lib
    provide port structContainer: provided-interface=StructContainerInterface
    provide port cameraStructContainer: provided-interface=CameraStructContainerInterface
    require port structContainer: required-interface=StructContainerInterface
    require port cameraStructContainer: required-interface=CameraStructContainerInterface
    provide port alarmInfo: provided-interface=FmAlarmReceiveService
    require port alarmInfo: required-interface=FmAlarmReceiveService
    require port alarmInfo1: required-interface=FmAlarmReceiveService
    provide port clientServiceContainer: provided-interface=ClientServiceContainerInterface
    require port clientServiceContainer1: required-interface=ClientServiceContainerInterface
    require port clientServiceContainer: required-interface=ClientServiceContainerInterface
  adaptive application sw component type hmi_service_lib
    require port IflytekAlarmInfoHmiService: required-interface=FmAlarmReceiveService
    provide port IflytekHmiInner: provided-interface=StructContainerInterface
    provide port IflytekHmiSocToMcuBsw: provided-interface=StructContainerInterface
    5 x require port, all with required-interface=StructContainerInterface:
      IflytekVehicleService
      IflytekHmiMcuToSocBsw
      IflytekFsmHmiSocOuter
      IflytekFsmSocState
      IflytekCameraPerceptionOccupancyObjects
    provide port IflytekEngineerInner: provided-interface=StructContainerInterface
    require port IflytekAlarmInfoFmAService: required-interface=StructContainerInterface
    provide port IflytekHmiPhmReport: provided-interface=StructContainerInterface
    4 x require port, all with required-interface=StructContainerInterface:
      IflytekCameraPerception3dOccupancyObjects
      IflytekLocalizationEgomotion
      IflytekCameraPerceptionDrivableSpaceGrid
      IflytekEhpParkingMapToHmi
  adaptive application sw component type radar_4d_service_lib
    provide port IflytekRadarFmPerception4dTarget: provided-interface=StructContainerInterface
    provide port IflytekRadarFmPerception4dPointCloud: provided-interface=StructContainerInterface
    require port IflytekAlarmInfoRadar4dService: required-interface=FmAlarmReceiveService
    provide port IflytekRadarPerception4dTargetMcu: provided-interface=StructContainerInterface
    provide port Iflytek4dRadarPhmReport: provided-interface=StructContainerInterface
  adaptive application sw component type sdmap_lib
    provide port IflytekSdmapSdmapInfo: provided-interface=StructContainerInterface
    require port IflytekAlarmInfoSdmap: required-interface=FmAlarmReceiveService
    require port IflytekLocalizationEgomotion: required-interface=StructContainerInterface
    require port IflytekSensorGnss: required-interface=StructContainerInterface
  adaptive application sw component type mega_lib
    provide port IflytekMegaLocalMap: provided-interface=StructContainerInterface
    7 x require port:
      IflytekCameraPerceptionParkingSlotList: required-interface=StructContainerInterface
      IflytekCameraPerceptionDeceler: required-interface=StructContainerInterface
      IflytekCameraPerceptionGroundLine: required-interface=StructContainerInterface
      IflytekCameraPerceptionParkingLaneLine: required-interface=StructContainerInterface
      IflytekLocalizationEgomotion: required-interface=StructContainerInterface
      IflytekAlarmInfoMega: required-interface=FmAlarmReceiveService
      IflytekLocalizationSemanticInfo: required-interface=StructContainerInterface
    provide port IflytekMegaMappingStatus: provided-interface=StructContainerInterface
    4 x require port, all with required-interface=StructContainerInterface:
      IflytekCameraPerception3dGeneralObjects
      IflytekFusionSpatialParkingSlot
      IflytekFsmSocState
      IflytekVehicleService
    provide port IflytekMegaPhmReport: provided-interface=StructContainerInterface
    require port IflytekEhpParkingMapFileInfo: required-interface=StructContainerInterface
  adaptive application sw component type panorama_view_camera_perception_laneline_lib
    provide port IflytekCameraPerceptionLaneLines: provided-interface=StructContainerInterface
    provide port IflytekCameraPerceptionLaneTopo: provided-interface=StructContainerInterface
    require port IflytekAlarmInfoPanoramaViewCameraPerceptionLaneline: required-interface=FmAlarmReceiveService
    require port IflytekLocalizationEgomotion: required-interface=StructContainerInterface
    provide port IflytekPredictionPredictionResult: provided-interface=StructContainerInterface
    provide port IflytekCameraPerceptionObjects: provided-interface=StructContainerInterface
    require port IflytekVehicleService: required-interface=StructContainerInterface
    require port IflytekFsmSocState: required-interface=StructContainerInterface
    provide port IflytekCameraPerceptionPanoramaView2DBoundingBoxes: provided-interface=StructContainerInterface
    provide port IflytekCameraPerceptionPanoramaLanelinePhmReport: provided-interface=StructContainerInterface
    provide port IflytekCameraPerceptionDrivableSpaceGrid: provided-interface=StructContainerInterface
    require port IflytekCameraPerceptionObstacleFeature: required-interface=CameraStructContainerInterface
    require port IflytekCameraPerceptionLaneFeature: required-interface=CameraStructContainerInterface
  adaptive application sw component type around_view_camera_perception_lib
    4 x require port, all with required-interface=CameraStructContainerInterface:
      IflytekSensorCameraSurroundResizeImageFront
      IflytekSensorCameraSurroundResizeImageLeft
      IflytekSensorCameraSurroundResizeImageRight
      IflytekSensorCameraSurroundResizeImageRear
    provide port IflytekCameraPerception3dGeneralObjects: provided-interface=StructContainerInterface
    provide port IflytekCameraPerceptionOccupancyObjects: provided-interface=StructContainerInterface
    require port IflytekAlarmInfoAroundViewCameraPerception: required-interface=FmAlarmReceiveService
    4 x provide port, all with provided-interface=StructContainerInterface:
      IflytekCameraPerceptionParkingSlotList
      IflytekCameraPerceptionGroundLine
      IflytekCameraPerceptionParkingLaneLine
      IflytekCameraPerceptionDeceler
    4 x require port, all with required-interface=StructContainerInterface:
      IflytekLocalizationEgomotion
      IflytekUssUsswaveInfo
      IflytekVehicleService
      IflytekFsmSocState
    provide port IflytekCameraPerceptionAroundView2DBoundingBoxes: provided-interface=StructContainerInterface
    provide port IflytekCameraPerceptionAroundPhmReport: provided-interface=StructContainerInterface
    provide port IflytekCameraPerception3dOccupancyObjects: provided-interface=StructContainerInterface
  adaptive application sw component type fm_a_service_lib
    7 x provide port, all with provided-interface=FmAlarmReceiveService:
      IflytekAlarmInfoCameraNodeAroundView
      IflytekAlarmInfoAroundViewCameraPerception
      IflytekAlarmInfoSocACommunication
      IflytekAlarmInfoPanoramaViewCameraPerceptionLaneline
      IflytekAlarmInfoMdcA
      IflytekAlarmInfoMega
      IflytekAlarmInfoStaticFusion
    6 x require port:
      IflytekSensorGetSurroundCameraIntriParam: required-interface=ClientServiceContainerInterface
      IflytekSensorGetPanoramaCameraIntriParam: required-interface=ClientServiceContainerInterface
      IflytekSensorWriteFile: required-interface=ClientServiceContainerInterface
      IflytekFactoryCalibrationActivation: required-interface=ClientServiceContainerInterface
      IflytekFactoryCalibrationResult: required-interface=ClientServiceContainerInterface
      IflytekStateManager: required-interface=TriggerInOut
    provide port IflytekFmMcuInfo: provided-interface=StructContainerInterface
    require port IflytekAlarmInfoSoc: required-interface=StructContainerInterface
    require port IflytekSensorMcuToFmInfo: required-interface=StructContainerInterface
    require port IflytekAlarmInfoMcu: required-interface=StructContainerInterface
    5 x provide port, all with provided-interface=FmAlarmReceiveService:
      IflytekAlarmInfoComServicePncNode
      IflytekAlarmInfoObstacleFusion
      IflytekAlarmInfoPlanning
      IflytekAlarmInfoOtaNode
      IflytekAlarmInfoControl
    require port IflytekConfigManager: required-interface=ConfigServerServiceInterface
    provide port IflytekAlarmInfoFmAService: provided-interface=StructContainerInterface
    provide port IflytekDTCInfoFmAService: provided-interface=StructContainerInterface
    4 x require port:
      IflytekPostSaleCalibrationActivation: required-interface=ClientServiceContainerInterface
      IflytekPostSaleCalibrationStop: required-interface=ClientServiceContainerInterface
      IflytekPostSaleCalibrationResult: required-interface=ClientServiceContainerInterface
      IflytekVehicleService: required-interface=StructContainerInterface
    provide port IflytekAlarmInfoToACamera: provided-interface=StructContainerInterface
    require port IflytekMcuFmASentinel: required-interface=StructContainerInterface
    provide port IflytekFmAMcuSentinel: provided-interface=StructContainerInterface
    provide port IflytekFmACameraSentinel: provided-interface=StructContainerInterface
    require port IflytekEngineerInner: required-interface=StructContainerInterface
    provide port IflytekFmAMcuDegradeFunciton: provided-interface=StructContainerInterface
    provide port IflytekFmADegradeFunciton: provided-interface=StructContainerInterface
    provide port IflytekAlarmInfoPhmA: provided-interface=FmAlarmReceiveService
    require port IflytekCameraState: required-interface=StructContainerInterface
    require port IflytekFdlUploadState: required-interface=StructContainerInterface
    require port IflytekFdlNetStatCheck: required-interface=ClientServiceContainerInterface
    provide port IflytekAlarmInfoEhp: provided-interface=FmAlarmReceiveService
    4 x require port:
      IflytekDiskSpaceInfoPhmAOta: required-interface=StructContainerInterface
      IflytekDiskSpaceInfoPhmBOta: required-interface=StructContainerInterface
      IflytekObdUpdateEvent: required-interface=ClientServiceContainerInterface
      IflytekCalibrationCalibInfo: required-interface=StructContainerInterface
  adaptive application sw component type fm_b_service_lib
    17 x provide port:
      IflytekAlarmInfoSdmap: provided-interface=FmAlarmReceiveService
      IflytekAlarmInfoGnssServiceNode: provided-interface=FmAlarmReceiveService
      IflytekAlarmInfoEhr: provided-interface=FmAlarmReceiveService
      IflytekAlarmInfoLocalization: provided-interface=FmAlarmReceiveService
      IflytekAlarmInfoSocBCommunication: provided-interface=FmAlarmReceiveService
      IflytekAlarmInfoCameraNodePanoramaView: provided-interface=FmAlarmReceiveService
      IflytekAlarmInfoPanoramaViewCameraPerception: provided-interface=FmAlarmReceiveService
      IflytekAlarmInfoHmiService: provided-interface=FmAlarmReceiveService
      IflytekAlarmInfoMdcB: provided-interface=FmAlarmReceiveService
      IflytekAlarmInfoSoc: provided-interface=StructContainerInterface
      IflytekAlarmInfoRadar4dService: provided-interface=FmAlarmReceiveService
      IflytekAlarmInfoCalibration: provided-interface=FmAlarmReceiveService
      IflytekAlarmInfoEhp: provided-interface=FmAlarmReceiveService
      IflytekAlarmInfoFiniteStateManager: provided-interface=FmAlarmReceiveService
      IflytekAlarmInfoFdl: provided-interface=FmAlarmReceiveService
      IflytekAlarmInfoToBCamera: provided-interface=StructContainerInterface
      IflytekAlarmInfoPhmB: provided-interface=FmAlarmReceiveService
  adaptive application sw component type mdc_a_fm_lib
    provide port IflytekConfigManager: provided-interface=ConfigServerServiceInterface
    provide port IflytekStateManager: provided-interface=TriggerInOut
    require port IflytekAlarmInfoMdcA: required-interface=FmAlarmReceiveService
  adaptive application sw component type mdc_b_fm_lib
    require port IflytekAlarmInfoMdcB: required-interface=FmAlarmReceiveService
  adaptive application sw component type calibration_lib
    require port IflytekSensorCameraRear_copy: required-interface=CameraStructContainerInterface
    require port IflytekSensorCameraRear_copy: required-interface=CameraStructContainerInterface
    require port IflytekSensorCameraRear_copy: required-interface=CameraStructContainerInterface
    provide port IflytekCalibrationCalibInfo: provided-interface=StructContainerInterface
    14 x require port:
      IflytekSensorCameraRear_copy: required-interface=CameraStructContainerInterface
      IflytekSensorCameraSideRr: required-interface=CameraStructContainerInterface
      IflytekSensorCameraSideRl: required-interface=CameraStructContainerInterface
      IflytekSensorCameraSideFl: required-interface=CameraStructContainerInterface
      IflytekSensorCameraFront30: required-interface=CameraStructContainerInterface
      IflytekSensorCameraFront120FullResolutionH265: required-interface=CameraStructContainerInterface
      IflytekSensorCameraSurroundResizeImageRear: required-interface=CameraStructContainerInterface
      IflytekSensorCameraSurroundResizeImageRight: required-interface=CameraStructContainerInterface
      IflytekAlarmInfoCalibration: required-interface=FmAlarmReceiveService
      IflytekSensorImu: required-interface=StructContainerInterface
      IflytekVehicleService: required-interface=StructContainerInterface
      IflytekLocalizationEgomotion: required-interface=StructContainerInterface
      IflytekCameraPerceptionObjects: required-interface=StructContainerInterface
      IflytekFusionObjects: required-interface=StructContainerInterface
    provide port IflytekPostSaleCalibrationStop: provided-interface=ClientServiceContainerInterface
    provide port IflytekPostSaleCalibrationActivation: provided-interface=ClientServiceContainerInterface
    provide port IflytekPostSaleCalibrationResult: provided-interface=ClientServiceContainerInterface
    6 x require port:
      IflytekSensorCameraSurroundResizeImageLeft: required-interface=CameraStructContainerInterface
      IflytekSensorCameraSurroundResizeImageFront: required-interface=CameraStructContainerInterface
      IflytekFsmSocState: required-interface=StructContainerInterface
      IflytekSensorCameraSideFr: required-interface=CameraStructContainerInterface
      IflytekSensorCameraRear: required-interface=CameraStructContainerInterface
      IflytekSensorCameraFront120FullResolutionClearH265: required-interface=CameraStructContainerInterface
    provide port IflytekCalibrationPhmReport: provided-interface=StructContainerInterface
    provide port IflytekCalibrationDebugInfo: provided-interface=StructContainerInterface
  adaptive application sw component type ehp_lib
    4 x provide port, all with provided-interface=StructContainerInterface:
      IflytekEhpParkingMap
      IflytekEhpParkingMapFileInfo
      IflytekEhpMapManager
      IflytekEhpPhmReport
    5 x require port:
      IflytekAlarmInfoEhp: required-interface=FmAlarmReceiveService
      IflytekLocalizationSemanticInfo: required-interface=StructContainerInterface
      IflytekMegaMappingStatus: required-interface=StructContainerInterface
      IflytekSensorGnss: required-interface=StructContainerInterface
      IflytekFsmSocState: required-interface=StructContainerInterface
    provide port IflytekEhpParkingMapToHmi: provided-interface=StructContainerInterface
  adaptive application sw component type ApplicationSwc
  adaptive application sw component type factory_calibration_lib
    provide port IflytekFactoryCalibrationActivation: provided-interface=ClientServiceContainerInterface
    provide port IflytekFactoryCalibrationResult: provided-interface=ClientServiceContainerInterface
    12 x require port:
      IflytekSensorCameraSurroundFrontFullResolutionH265: required-interface=CameraStructContainerInterface
      IflytekSensorCameraSurroundLeftFullResolutionH265: required-interface=CameraStructContainerInterface
      IflytekSensorCameraSurroundRearFullResolutionH265: required-interface=CameraStructContainerInterface
      IflytekSensorCameraSurroundRightFullResolutionH265: required-interface=CameraStructContainerInterface
      IflytekSensorCameraFront30FullResolutionH265: required-interface=CameraStructContainerInterface
      IflytekSensorCameraFront120FullResolutionH265: required-interface=CameraStructContainerInterface
      IflytekSensorCameraSideFlFullResolutionH265: required-interface=CameraStructContainerInterface
      IflytekSensorCameraSideFrFullResolutionH265: required-interface=CameraStructContainerInterface
      IflytekSensorCameraSideRlFullResolutionH265: required-interface=CameraStructContainerInterface
      IflytekSensorCameraSideRrFullResolutionH265: required-interface=CameraStructContainerInterface
      IflytekSensorCameraRearFullResolutionH265MDCA: required-interface=CameraStructContainerInterface
      IflytekSensorImu: required-interface=StructContainerInterface
  adaptive application sw component type ApplicationSwc
  adaptive application sw component type lidar_node_lib
  adaptive application sw component type ota_node_lib
    4 x require port:
      IflytekConfigManager: required-interface=ConfigServerServiceInterface
      IflytekAlarmInfoOtaNode: required-interface=FmAlarmReceiveService
      IflytekDiskSpaceInfoPhmAOta: required-interface=StructContainerInterface
      IflytekDiskSpaceInfoPhmBOta: required-interface=StructContainerInterface
    provide port IflytekDiskCleanRequest: provided-interface=StructContainerInterface
    provide port IflytekObdUpdateEvent: provided-interface=ClientServiceContainerInterface
    require port IflytekOtaLogUploadRequest: required-interface=ClientServiceContainerInterface
  adaptive application sw component type function_data_loop_lib
    60 x require port:
      IflytekCalibrationCalibInfo: required-interface=StructContainerInterface
      IflytekSensorCameraSurroundFrontFullResolutionH265: required-interface=CameraStructContainerInterface
      IflytekSensorCameraSurroundLeftFullResolutionH265: required-interface=CameraStructContainerInterface
      IflytekSensorCameraSurroundRearFullResolutionH265: required-interface=CameraStructContainerInterface
      IflytekSensorCameraSurroundRightFullResolutionH265: required-interface=CameraStructContainerInterface
      IflytekSensorCameraFront120FullResolutionH265: required-interface=CameraStructContainerInterface
      IflytekSensorCameraFront30FullResolutionH265: required-interface=CameraStructContainerInterface
      IflytekSensorCameraSideFlFullResolutionH265: required-interface=CameraStructContainerInterface
      IflytekSensorCameraSideFrFullResolutionH265: required-interface=CameraStructContainerInterface
      IflytekSensorCameraSideRlFullResolutionH265: required-interface=CameraStructContainerInterface
      IflytekSensorCameraSideRrFullResolutionH265: required-interface=CameraStructContainerInterface
      IflytekSensorCameraRearFullResolutionH265: required-interface=CameraStructContainerInterface
      IflytekCameraPerceptionTrafficSignRecognition: required-interface=StructContainerInterface
      IflytekCameraPerceptionOccGrid: required-interface=StructContainerInterface
      IflytekCameraPerceptionLaneTopo: required-interface=StructContainerInterface
      IflytekPredictionPredictionResult: required-interface=StructContainerInterface
      IflytekCameraPerceptionLaneLines: required-interface=StructContainerInterface
      IflytekCameraPerceptionObjects: required-interface=StructContainerInterface
      IflytekCameraPerceptionOccupancyObjects: required-interface=StructContainerInterface
      IflytekCameraPerception3dGeneralObjects: required-interface=StructContainerInterface
      IflytekCameraPerceptionParkingSlotList: required-interface=StructContainerInterface
      IflytekCameraPerceptionParkingLaneLine: required-interface=StructContainerInterface
      IflytekCameraPerceptionGroundLine: required-interface=StructContainerInterface
      IflytekCameraPerceptionDeceler: required-interface=StructContainerInterface
      IflytekFusionSpatialParkingSlot: required-interface=StructContainerInterface
      IflytekFusionParkingSlot: required-interface=StructContainerInterface
      IflytekFusionRoadFusion: required-interface=StructContainerInterface
      IflytekFusionObjects: required-interface=StructContainerInterface
      IflytekFusionObjectsCompress: required-interface=StructContainerInterface
      IflytekFusionUssPerceptionInfo: required-interface=StructContainerInterface
      IflytekFusionOccupancyObjects: required-interface=StructContainerInterface
      IflytekFusionRoadFusionCompress: required-interface=StructContainerInterface
      IflytekFusionGroundLine: required-interface=StructContainerInterface
      IflytekFusionSpeedBump: required-interface=StructContainerInterface
      IflytekMegaLocalMap: required-interface=StructContainerInterface
      IflytekMegaMappingStatus: required-interface=StructContainerInterface
      IflytekUssUsswaveInfo: required-interface=StructContainerInterface
      IflytekRadarFlPerceptionInfo: required-interface=StructContainerInterface
      IflytekRadarFrPerceptionInfo: required-interface=StructContainerInterface
      IflytekRadarRlPerceptionInfo: required-interface=StructContainerInterface
      IflytekRadarRrPerceptionInfo: required-interface=StructContainerInterface
      IflytekRadarFmPerception4dPointCloud: required-interface=StructContainerInterface
      IflytekRadarFmPerception4dTarget: required-interface=StructContainerInterface
      IflytekSensorImu: required-interface=StructContainerInterface
      IflytekVehicleService: required-interface=StructContainerInterface
      IflytekSensorGnss: required-interface=StructContainerInterface
      IflytekLocalizationEgomotion: required-interface=StructContainerInterface
      IflytekLocalizationSemanticInfo: required-interface=StructContainerInterface
      IflytekEhrSdmapInfo: required-interface=StructContainerInterface
      IflytekEhrStaticMap: required-interface=StructContainerInterface
      IflytekEhrSdpromapInfo: required-interface=StructContainerInterface
      IflytekHmiInner: required-interface=StructContainerInterface
      IflytekFsmSocState: required-interface=StructContainerInterface
      IflytekFsmHmiSocOuter: required-interface=StructContainerInterface
      IflytekAdasFunctionAdas: required-interface=StructContainerInterface
      IflytekControlControlCommand: required-interface=StructContainerInterface
      IflytekPlanningPlan: required-interface=StructContainerInterface
      IflytekPlanningHmi: required-interface=StructContainerInterface
      IflytekSdmapSdmapInfo: required-interface=StructContainerInterface
      IflytekAlarmInfoFdl: required-interface=FmAlarmReceiveService
    provide port IflytekFdlUploadState: provided-interface=StructContainerInterface
    4 x require port:
      IflytekDTCInfoFmAService: required-interface=StructContainerInterface
      IflytekAlarmInfoFmAService: required-interface=StructContainerInterface
      IflytekConfigManager: required-interface=ConfigServerServiceInterface
      IflytekSystemVersion: required-interface=StructContainerInterface
    provide port IflytekFdlTrigger: provided-interface=StructContainerInterface
    12 x require port:
      IflytekFdlTriggerAck: required-interface=StructContainerInterface
      IflytekPlanningDebugInfo: required-interface=StructContainerInterface
      IflytekControlDebugInfo: required-interface=StructContainerInterface
      IflytekAdasFunctionDebugInfo: required-interface=StructContainerInterface
      IflytekSensorCameraRearFullResolutionH265MDCA: required-interface=CameraStructContainerInterface
      IflytekFmAMcuSentinel: required-interface=StructContainerInterface
      IflytekMcuFmASentinel: required-interface=StructContainerInterface
      IflytekFmADegradeFunciton: required-interface=StructContainerInterface
      IflytekEngineerInner: required-interface=StructContainerInterface
      IflytekCameraPerceptionAroundView2DBoundingBoxes: required-interface=StructContainerInterface
      IflytekCameraPerceptionPanoramaView2DBoundingBoxes: required-interface=StructContainerInterface
      IflytekCameraPerceptionScene: required-interface=StructContainerInterface
    provide port IflytekFdlNetStatCheck: provided-interface=ClientServiceContainerInterface
    5 x require port, all with required-interface=StructContainerInterface:
      IflytekDiskStatePhmAFdl
      IflytekDiskCleanRequestPhmAFdl
      IflytekDiskStatePhmBFdl
      IflytekDiskCleanRequestPhmBFdl
      IflytekSystemBProcessLoading
    provide port IflytekFdlPhmReport: provided-interface=StructContainerInterface
    4 x require port, all with required-interface=StructContainerInterface:
      IflytekCalibrationDebugInfo
      IflytekEhpParkingMap
      IflytekEhpParkingMapFileInfo
      IflytekEhpMapManager
    provide port IflytekOtaLogUploadRequest: provided-interface=ClientServiceContainerInterface
    4 x require port, all with required-interface=StructContainerInterface:
      IflytekSystemAProcessLoading
      IflytekCameraPerceptionDrivableSpaceGrid
      IflytekEhpParkingMapToHmi
      IflytekCanTxInfo
  adaptive application sw component type function_data_loop_a_lib
    provide port IflytekFdlTriggerAck: provided-interface=StructContainerInterface
    require port IflytekFdlTrigger: required-interface=StructContainerInterface
    require port IflytekSystemAProcessLoading: required-interface=StructContainerInterface
    provide port IflytekFdlAPhmReport: provided-interface=StructContainerInterface
  adaptive application sw component type soc_b_phm_lib
    11 x require port:
      IflytekAlarmInfoPhmB: required-interface=FmAlarmReceiveService
      IflytekEhrPhmReport: required-interface=StructContainerInterface
      IflytekLocalizationPhmReport: required-interface=StructContainerInterface
      IflytekGnssPhmReport: required-interface=StructContainerInterface
      IflytekHmiPhmReport: required-interface=StructContainerInterface
      Iflytek4dRadarPhmReport: required-interface=StructContainerInterface
      IflytekCameraPerceptionPanoramaPhmReport: required-interface=StructContainerInterface
      IflytekFsmPhmReport: required-interface=StructContainerInterface
      IflytekCameraPanoramaPhmReport: required-interface=StructContainerInterface
      IflytekConfigManager: required-interface=ConfigServerServiceInterface
      IflytekStateManager: required-interface=TriggerInOut
    provide port IflytekDiskSpaceInfoPhmBOta: provided-interface=StructContainerInterface
    require port IflytekDiskCleanRequest: required-interface=StructContainerInterface
    provide port IflytekDiskStatePhmBFdl: provided-interface=StructContainerInterface
    provide port IflytekDiskCleanRequestPhmBFdl: provided-interface=StructContainerInterface
    require port IflytekCalibrationPhmReport: required-interface=StructContainerInterface
    require port IflytekFdlPhmReport: required-interface=StructContainerInterface
  adaptive application sw component type ApplicationSwc
  adaptive application sw component type soc_a_phm_lib
    12 x require port:
      IflytekCameraPerceptionPanoramaLanelinePhmReport: required-interface=StructContainerInterface
      IflytekFusionObstaclePhmReport: required-interface=StructContainerInterface
      IflytekPlanningPhmReport: required-interface=StructContainerInterface
      IflytekComPncPhmReport: required-interface=StructContainerInterface
      IflytekCameraPerceptionAroundPhmReport: required-interface=StructContainerInterface
      IflytekCameraAroundPhmReport: required-interface=StructContainerInterface
      IflytekMegaPhmReport: required-interface=StructContainerInterface
      IflytekControlPhmReport: required-interface=StructContainerInterface
      IflytekFusionStaticPhmReport: required-interface=StructContainerInterface
      IflytekAlarmInfoPhmA: required-interface=FmAlarmReceiveService
      IflytekConfigManager: required-interface=ConfigServerServiceInterface
      IflytekStateManager: required-interface=TriggerInOut
    provide port IflytekDiskSpaceInfoPhmAOta: provided-interface=StructContainerInterface
    require port IflytekDiskCleanRequest: required-interface=StructContainerInterface
    provide port IflytekDiskStatePhmAFdl: provided-interface=StructContainerInterface
    provide port IflytekDiskCleanRequestPhmAFdl: provided-interface=StructContainerInterface
    require port IflytekFdlAPhmReport: required-interface=StructContainerInterface
    require port IflytekEhpPhmReport: required-interface=StructContainerInterface
  adaptive application sw component type system_monitor_b_lib
    provide port IflytekSystemBProcessLoading: provided-interface=StructContainerInterface
  adaptive application sw component type system_monitor_a_lib
    provide port IflytekSystemAProcessLoading: provided-interface=StructContainerInterface
package /HuaweiMDC/exe_manifests/exes
  18 x executable, all with logging-behavior=USES-LOGGING, reporting-behavior=REPORTS-EXECUTION-STATE:
    com_service_pnc_node_exec
      root sw component prototype com_service_pnc_node_libExecutable1Prototype: application-type=com_service_pnc_node_libCompositionSwComponentType1
    control_exec
      root sw component prototype control_libExecutable2Prototype: application-type=control_libCompositionSwComponentType2
    obstacle_fusion_exec
      root sw component prototype obstacle_fusion_libExecutable3Prototype: application-type=obstacle_fusion_libCompositionSwComponentType3
    static_fusion_exec
      root sw component prototype static_fusion_libExecutable4Prototype: application-type=static_fusion_libCompositionSwComponentType4
    finite_state_manager_exec
      root sw component prototype finite_state_manager_libExecutable5Prototype: application-type=finite_state_manager_libCompositionSwComponentType5
    localization_exec
      root sw component prototype localization_libExecutable7Prototype: application-type=localization_libCompositionSwComponentType7
    ehr_exec
      root sw component prototype ehr_libExecutable8Prototype: application-type=ehr_libCompositionSwComponentType8
    panorama_view_camera_perception_exec
      root sw component prototype panorama_view_camera_perception_libExecutable10Prototype: application-type=panorama_view_camera_perception_libCompositionSwComponentType10
    uss_perception_exec
      root sw component prototype uss_perception_libExecutable12Prototype: application-type=uss_perception_libCompositionSwComponentType12
    planning_exec
      root sw component prototype planning_libExecutable13Prototype: application-type=planning_libCompositionSwComponentType13
    camera_node_around_view_exec
      root sw component prototype camera_node_around_view_libExecutable15Prototype: application-type=camera_node_around_view_libCompositionSwComponentType15
    camera_node_panorama_view_exec
      root sw component prototype camera_node_panorama_view_libExecutable16Prototype: application-type=camera_node_panorama_view_libCompositionSwComponentType16
    gnss_service_node_exec
      root sw component prototype gnss_service_node_libExecutable17Prototype: application-type=gnss_service_node_libCompositionSwComponentType17
    soc_a_communication_exec
      root sw component prototype soc_a_communication_libExecutable18Prototype: application-type=soc_a_communication_libCompositionSwComponentType18
    soc_b_communication_exec
      root sw component prototype soc_b_communication_libExecutable19Prototype: application-type=soc_b_communication_libCompositionSwComponentType19
    common_swc_exec1
      root sw component prototype common_swc_libExecutable22Prototype: application-type=common_swc_libCompositionSwComponentType22
    common_swc_exec2
      root sw component prototype common_swc_libExecutable23Prototype: application-type=common_swc_libCompositionSwComponentType23
    calibration_exec
      root sw component prototype calibration_libExecutable20Prototype: application-type=calibration_libCompositionSwComponentType20
